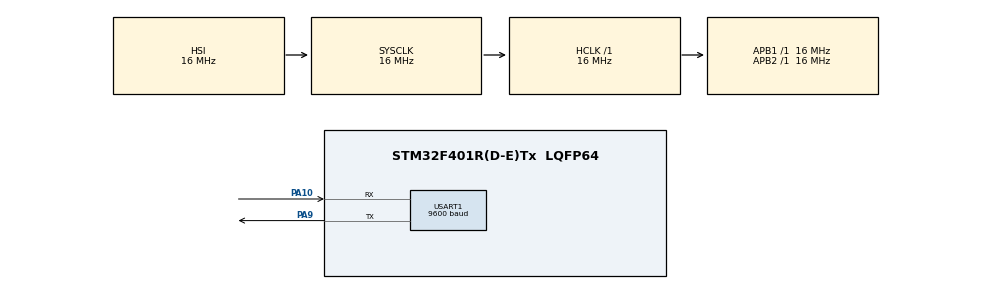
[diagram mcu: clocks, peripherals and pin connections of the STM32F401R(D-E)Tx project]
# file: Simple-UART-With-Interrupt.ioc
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Mcu.Family=STM32F4
RCC.VCOOutputFreq_Value=192000000
RCC.APB2Freq_Value=16000000
RCC.CortexFreq_Value=16000000
PA10.Mode=Asynchronous
USART1.BaudRate=9600
Mcu.Name=STM32F401R(D-E)Tx
RCC.SYSCLKFreq_VALUE=16000000
Mcu.Package=LQFP64
ProjectManager.StackSize=0x400
USART1.VirtualMode=VM_ASYNC
PA9.Mode=Asynchronous
PA10.Signal=USART1_RX
ProjectManager.HeapSize=0x200
ProjectManager.TargetToolchain=MDK-ARM V5.27
RCC.HSI_VALUE=16000000
NVIC.PriorityGroup=NVIC_PRIORITYGROUP_4
PA9.Signal=USART1_TX
NVIC.USART1_IRQn=true\:0\:0\:false\:false\:true\:true\:true
RCC.APB1Freq_Value=16000000
RCC.LSE_VALUE=32768
RCC.AHBFreq_Value=16000000
RCC.HSE_VALUE=25000000
board=custom

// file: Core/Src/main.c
/* USER CODE BEGIN Header */
/**
  ******************************************************************************
  * @file           : main.c
  * @brief          : Main program body
  ******************************************************************************
  * @attention
  *
  * <h2><center>&copy; Copyright (c) 2020 STMicroelectronics.
  * All rights reserved.</center></h2>
  *
  * This software component is licensed by ST under BSD 3-Clause license,
  * the "License"; You may not use this file except in compliance with the
  * License. You may obtain a copy of the License at:
  *                        opensource.org/licenses/BSD-3-Clause
  *
  ******************************************************************************
  */
/* USER CODE END Header */
#include "main.h"

UART_HandleTypeDef huart1;

/* USER CODE BEGIN PV */
uint8_t buffer[] = "";
/* USER CODE END PV */

void SystemClock_Config(void);
static void MX_GPIO_Init(void);
static void MX_USART1_UART_Init(void);
/* USER CODE BEGIN PFP */
void HAL_UART_RxCpltCallback(UART_HandleTypeDef *huart);
/* USER CODE END PFP */

int main(void)
{

  /* MCU Configuration--------------------------------------------------------*/

  /* Reset of all peripherals, Initializes the Flash interface and the Systick. */
  HAL_Init();

  /* Configure the system clock */
  SystemClock_Config();

  /* Initialize all configured peripherals */
  MX_GPIO_Init();
  MX_USART1_UART_Init();
  /* USER CODE BEGIN 2 */
	HAL_UART_Receive_IT(&huart1, buffer, sizeof(buffer));
  /* USER CODE END 2 */

  /* Infinite loop */
  while (1)
  {
  }
}

void SystemClock_Config(void)
{
  RCC_OscInitTypeDef RCC_OscInitStruct = {0};
  RCC_ClkInitTypeDef RCC_ClkInitStruct = {0};

  /** Configure the main internal regulator output voltage
  */
  __HAL_RCC_PWR_CLK_ENABLE();
  __HAL_PWR_VOLTAGESCALING_CONFIG(PWR_REGULATOR_VOLTAGE_SCALE2);
  /** Initializes the RCC Oscillators according to the specified parameters
  * in the RCC_OscInitTypeDef structure.
  */
  RCC_OscInitStruct.OscillatorType = RCC_OSCILLATORTYPE_HSI;
  RCC_OscInitStruct.HSIState = RCC_HSI_ON;
  RCC_OscInitStruct.HSICalibrationValue = RCC_HSICALIBRATION_DEFAULT;
  RCC_OscInitStruct.PLL.PLLState = RCC_PLL_NONE;
  if (HAL_RCC_OscConfig(&RCC_OscInitStruct) != HAL_OK)
  {
    Error_Handler();
  }
  /** Initializes the CPU, AHB and APB buses clocks
  */
  RCC_ClkInitStruct.ClockType = RCC_CLOCKTYPE_HCLK|RCC_CLOCKTYPE_SYSCLK
                              |RCC_CLOCKTYPE_PCLK1|RCC_CLOCKTYPE_PCLK2;
  RCC_ClkInitStruct.SYSCLKSource = RCC_SYSCLKSOURCE_HSI;
  RCC_ClkInitStruct.AHBCLKDivider = RCC_SYSCLK_DIV1;
  RCC_ClkInitStruct.APB1CLKDivider = RCC_HCLK_DIV1;
  RCC_ClkInitStruct.APB2CLKDivider = RCC_HCLK_DIV1;

  if (HAL_RCC_ClockConfig(&RCC_ClkInitStruct, FLASH_LATENCY_0) != HAL_OK)
  {
    Error_Handler();
  }
}

static void MX_USART1_UART_Init(void)
{

  huart1.Instance = USART1;
  huart1.Init.BaudRate = 9600;
  huart1.Init.WordLength = UART_WORDLENGTH_8B;
  huart1.Init.StopBits = UART_STOPBITS_1;
  huart1.Init.Parity = UART_PARITY_NONE;
  huart1.Init.Mode = UART_MODE_TX_RX;
  huart1.Init.HwFlowCtl = UART_HWCONTROL_NONE;
  huart1.Init.OverSampling = UART_OVERSAMPLING_16;
  if (HAL_UART_Init(&huart1) != HAL_OK)
  {
    Error_Handler();
  }

}

static void MX_GPIO_Init(void)
{

  /* GPIO Ports Clock Enable */
  __HAL_RCC_GPIOA_CLK_ENABLE();

}

/* USER CODE BEGIN 4 */
void HAL_UART_RxCpltCallback(UART_HandleTypeDef *huart)
{
	HAL_UART_Transmit(huart, buffer, sizeof(buffer), HAL_MAX_DELAY);
	HAL_UART_Receive_IT(&huart1, buffer, sizeof(buffer));
}
/* USER CODE END 4 */

void Error_Handler(void)
{
}

/************************ (C) COPYRIGHT STMicroelectronics *****END OF FILE****/
